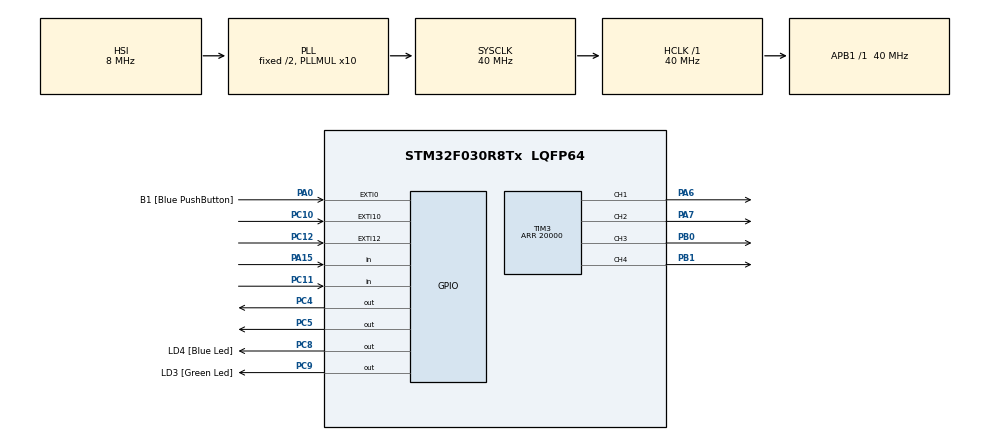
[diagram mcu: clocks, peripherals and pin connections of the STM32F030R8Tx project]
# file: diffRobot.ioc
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Mcu.Family=STM32F0
Mcu.Name=STM32F030R8Tx
Mcu.Package=LQFP64
PA0.GPIO_Label=B1 [Blue PushButton]
PA0.GPIO_ModeDefaultEXTI=GPIO_MODE_EVT_RISING
PA0.Signal=GPXTI0
PA13.GPIO_Label=SWDIO
PA13.Signal=SYS_SWDIO
PA14.GPIO_Label=SWCLK
PA14.Signal=SYS_SWCLK
PA15.Signal=GPIO_Input
PA6.Signal=S_TIM3_CH1
PA7.Signal=S_TIM3_CH2
PB0.Signal=S_TIM3_CH3
PB1.Signal=S_TIM3_CH4
PC10.GPIO_ModeDefaultEXTI=GPIO_MODE_IT_RISING_FALLING
PC10.Signal=GPXTI10
PC11.Signal=GPIO_Input
PC12.GPIO_ModeDefaultEXTI=GPIO_MODE_IT_RISING_FALLING
PC12.Signal=GPXTI12
PC4.Signal=GPIO_Output
PC5.Signal=GPIO_Output
PC8.GPIO_Label=LD4 [Blue Led]
PC8.Signal=GPIO_Output
PC9.GPIO_Label=LD3 [Green Led]
PC9.Signal=GPIO_Output
ProjectManager.HeapSize=0x200
ProjectManager.StackSize=0x400
ProjectManager.TargetToolchain=MDK-ARM V5
RCC.AHBFreq_Value=40000000
RCC.APB1Freq_Value=40000000
RCC.APB1TimFreq_Value=40000000
RCC.HCLKFreq_Value=40000000
RCC.PLLMUL=RCC_PLL_MUL10
RCC.SYSCLKFreq_VALUE=40000000
RCC.SYSCLKSource=RCC_SYSCLKSOURCE_PLLCLK
SH.S_TIM3_CH1.0=TIM3_CH1,PWM Generation1 CH1
SH.S_TIM3_CH2.0=TIM3_CH2,PWM Generation2 CH2
SH.S_TIM3_CH3.0=TIM3_CH3,PWM Generation3 CH3
SH.S_TIM3_CH4.0=TIM3_CH4,PWM Generation4 CH4
TIM3.Channel-PWM\ Generation2\ CH2=TIM_CHANNEL_2
TIM3.Channel-PWM\ Generation3\ CH3=TIM_CHANNEL_3
TIM3.Channel-PWM\ Generation4\ CH4=TIM_CHANNEL_4
TIM3.Period=20000
TIM3.Pulse-PWM\ Generation1\ CH1=10000
TIM3.Pulse-PWM\ Generation2\ CH2=10000
TIM3.Pulse-PWM\ Generation3\ CH3=10000
TIM3.Pulse-PWM\ Generation4\ CH4=10000
board=STM32F0308-DISCO

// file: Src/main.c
/**
  ******************************************************************************
  * File Name          : main.c
  * Description        : Main program body
  ******************************************************************************
  *
  * COPYRIGHT(c) 2017 STMicroelectronics
  *
  * Redistribution and use in source and binary forms, with or without modification,
  * are permitted provided that the following conditions are met:
  *   1. Redistributions of source code must retain the above copyright notice,
  *      this list of conditions and the following disclaimer.
  *   2. Redistributions in binary form must reproduce the above copyright notice,
  *      this list of conditions and the following disclaimer in the documentation
  *      and/or other materials provided with the distribution.
  *   3. Neither the name of STMicroelectronics nor the names of its contributors
  *      may be used to endorse or promote products derived from this software
  *      without specific prior written permission.
  *
  * THIS SOFTWARE IS PROVIDED BY THE COPYRIGHT HOLDERS AND CONTRIBUTORS "AS IS"
  * AND ANY EXPRESS OR IMPLIED WARRANTIES, INCLUDING, BUT NOT LIMITED TO, THE
  * IMPLIED WARRANTIES OF MERCHANTABILITY AND FITNESS FOR A PARTICULAR PURPOSE ARE
  * DISCLAIMED. IN NO EVENT SHALL THE COPYRIGHT HOLDER OR CONTRIBUTORS BE LIABLE
  * FOR ANY DIRECT, INDIRECT, INCIDENTAL, SPECIAL, EXEMPLARY, OR CONSEQUENTIAL
  * DAMAGES (INCLUDING, BUT NOT LIMITED TO, PROCUREMENT OF SUBSTITUTE GOODS OR
  * SERVICES; LOSS OF USE, DATA, OR PROFITS; OR BUSINESS INTERRUPTION) HOWEVER
  * CAUSED AND ON ANY THEORY OF LIABILITY, WHETHER IN CONTRACT, STRICT LIABILITY,
  * OR TORT (INCLUDING NEGLIGENCE OR OTHERWISE) ARISING IN ANY WAY OUT OF THE USE
  * OF THIS SOFTWARE, EVEN IF ADVISED OF THE POSSIBILITY OF SUCH DAMAGE.
  *
  ******************************************************************************
  */
#include "stm32f0xx_hal.h"
#include "tim.h"
#include "gpio.h"

/* USER CODE BEGIN PV */
/* Private variables ---------------------------------------------------------*/

/* USER CODE END PV */

void SystemClock_Config(void);
void Error_Handler(void);

/* USER CODE BEGIN PFP */
/* Private function prototypes -----------------------------------------------*/

/* USER CODE END PFP */

int main(void)
{

  /* MCU Configuration----------------------------------------------------------*/

  /* Reset of all peripherals, Initializes the Flash interface and the Systick. */
  HAL_Init();

  /* Configure the system clock */
  SystemClock_Config();

  /* Initialize all configured peripherals */
  MX_GPIO_Init();
  MX_TIM3_Init();

  /* USER CODE BEGIN 2 */
	motorForward(5000);
  /* USER CODE END 2 */

  /* Infinite loop */
  while (1)
  {

  /* USER CODE BEGIN 3 */
		motorForward(7000);
		HAL_Delay(2000);
		motorStop();
		HAL_Delay(2000);
		HAL_GPIO_WritePin(GPIOC,GPIO_PIN_5,1);
		motorForward(7000);
		HAL_Delay(2000);
		HAL_GPIO_WritePin(GPIOC,GPIO_PIN_5,0);
  }
  /* USER CODE END 3 */

}

/** System Clock Configuration
*/
void SystemClock_Config(void)
{

  RCC_OscInitTypeDef RCC_OscInitStruct;
  RCC_ClkInitTypeDef RCC_ClkInitStruct;

  RCC_OscInitStruct.OscillatorType = RCC_OSCILLATORTYPE_HSI;
  RCC_OscInitStruct.HSIState = RCC_HSI_ON;
  RCC_OscInitStruct.HSICalibrationValue = 16;
  RCC_OscInitStruct.PLL.PLLState = RCC_PLL_ON;
  RCC_OscInitStruct.PLL.PLLSource = RCC_PLLSOURCE_HSI;
  RCC_OscInitStruct.PLL.PLLMUL = RCC_PLL_MUL10;
  RCC_OscInitStruct.PLL.PREDIV = RCC_PREDIV_DIV1;
  if (HAL_RCC_OscConfig(&RCC_OscInitStruct) != HAL_OK)
  {
    Error_Handler();
  }

  RCC_ClkInitStruct.ClockType = RCC_CLOCKTYPE_HCLK|RCC_CLOCKTYPE_SYSCLK
                              |RCC_CLOCKTYPE_PCLK1;
  RCC_ClkInitStruct.SYSCLKSource = RCC_SYSCLKSOURCE_PLLCLK;
  RCC_ClkInitStruct.AHBCLKDivider = RCC_SYSCLK_DIV1;
  RCC_ClkInitStruct.APB1CLKDivider = RCC_HCLK_DIV1;
  if (HAL_RCC_ClockConfig(&RCC_ClkInitStruct, FLASH_LATENCY_1) != HAL_OK)
  {
    Error_Handler();
  }

  HAL_SYSTICK_Config(HAL_RCC_GetHCLKFreq()/1000);

  HAL_SYSTICK_CLKSourceConfig(SYSTICK_CLKSOURCE_HCLK);

  /* SysTick_IRQn interrupt configuration */
  HAL_NVIC_SetPriority(SysTick_IRQn, 0, 0);
}

void Error_Handler(void)
{
  while(1)
  {
  }
}

/************************ (C) COPYRIGHT STMicroelectronics *****END OF FILE****/
